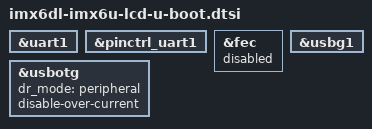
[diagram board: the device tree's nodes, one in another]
#include "imx6qdl-u-boot.dtsi"

&uart1 {
	bootph-all;
};

&pinctrl_uart1 {
	bootph-all;
};

&fec {
	status = "disabled";
};

&usbotg {
	dr_mode = "peripheral";
	disable-over-current;
	status = "okay";
};

&usbg1 {
	status = "okay";
};
